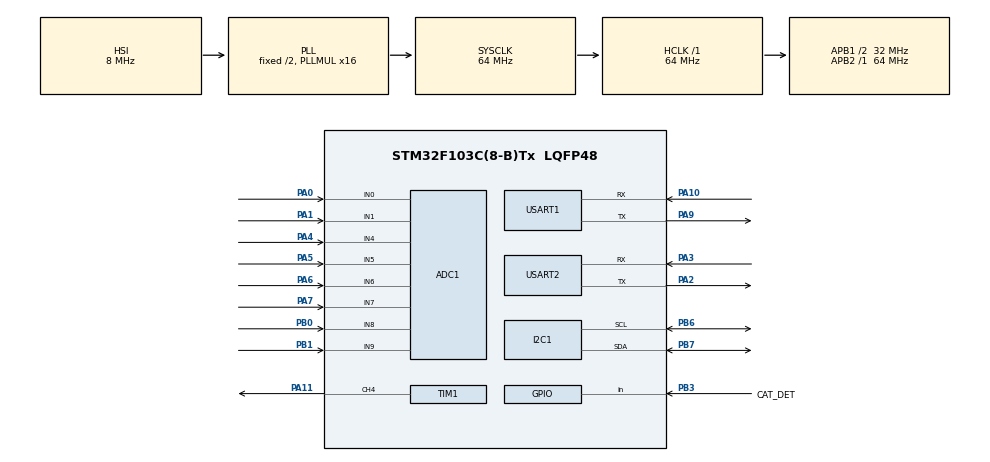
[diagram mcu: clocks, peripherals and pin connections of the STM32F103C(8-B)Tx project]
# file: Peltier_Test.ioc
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ADC1.Channel-0\#ChannelRegularConversion=ADC_CHANNEL_0
ADC1.NbrOfConversionFlag=1
ADC1.Rank-0\#ChannelRegularConversion=1
ADC1.SamplingTime-0\#ChannelRegularConversion=ADC_SAMPLETIME_1CYCLE_5
ADC1.master=1
Mcu.Family=STM32F1
Mcu.Name=STM32F103C(8-B)Tx
Mcu.Package=LQFP48
NVIC.PriorityGroup=NVIC_PRIORITYGROUP_4
NVIC.USART1_IRQn=true\:0\:0\:false\:false\:true\:true\:true\:true
NVIC.USART2_IRQn=true\:0\:0\:false\:false\:true\:true\:true\:true
PA0-WKUP.Signal=ADCx_IN0
PA1.Signal=ADCx_IN1
PA10.Mode=Asynchronous
PA10.Signal=USART1_RX
PA11.Signal=S_TIM1_CH4
PA13.Mode=Serial_Wire
PA13.Signal=SYS_JTMS-SWDIO
PA14.Mode=Serial_Wire
PA14.Signal=SYS_JTCK-SWCLK
PA2.Mode=Asynchronous
PA2.Signal=USART2_TX
PA3.Mode=Asynchronous
PA3.Signal=USART2_RX
PA4.Signal=ADCx_IN4
PA5.Signal=ADCx_IN5
PA6.Signal=ADCx_IN6
PA7.Signal=ADCx_IN7
PA9.Mode=Asynchronous
PA9.Signal=USART1_TX
PB0.Signal=ADCx_IN8
PB1.Signal=ADCx_IN9
PB3.GPIO_Label=CAT_DET
PB3.GPIO_PuPd=GPIO_PULLUP
PB3.Signal=GPIO_Input
PB6.Mode=I2C
PB6.Signal=I2C1_SCL
PB7.Mode=I2C
PB7.Signal=I2C1_SDA
ProjectManager.HeapSize=0x200
ProjectManager.StackSize=0x400
ProjectManager.TargetToolchain=STM32CubeIDE
RCC.ADCPresc=RCC_ADCPCLK2_DIV6
RCC.AHBFreq_Value=64000000
RCC.APB1CLKDivider=RCC_HCLK_DIV2
RCC.APB1Freq_Value=32000000
RCC.APB1TimFreq_Value=64000000
RCC.APB2Freq_Value=64000000
RCC.APB2TimFreq_Value=64000000
RCC.HCLKFreq_Value=64000000
RCC.PLLMUL=RCC_PLL_MUL16
RCC.SYSCLKFreq_VALUE=64000000
RCC.SYSCLKSource=RCC_SYSCLKSOURCE_PLLCLK
RCC.USBFreq_Value=64000000
SH.ADCx_IN0.0=ADC1_IN0,IN0
SH.ADCx_IN1.0=ADC1_IN1,IN1
SH.ADCx_IN4.0=ADC1_IN4,IN4
SH.ADCx_IN5.0=ADC1_IN5,IN5
SH.ADCx_IN6.0=ADC1_IN6,IN6
SH.ADCx_IN7.0=ADC1_IN7,IN7
SH.ADCx_IN8.0=ADC1_IN8,IN8
SH.ADCx_IN9.0=ADC1_IN9,IN9
SH.S_TIM1_CH4.0=TIM1_CH4,PWM Generation4 CH4
TIM1.Channel-PWM\ Generation4\ CH4=TIM_CHANNEL_4
TIM1.Period=9999
TIM1.Prescaler=64-1
TIM1.Pulse-PWM\ Generation4\ CH4=0
USART1.VirtualMode=VM_ASYNC
USART2.VirtualMode=VM_ASYNC
board=custom

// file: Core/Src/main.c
/* USER CODE BEGIN Header */
/**
  ******************************************************************************
  * @file           : main.c
  * @brief          : Main program body
  ******************************************************************************
  * @attention
  *
  * Copyright (c) 2025 STMicroelectronics.
  * All rights reserved.
  *
  * This software is licensed under terms that can be found in the LICENSE file
  * in the root directory of this software component.
  * If no LICENSE file comes with this so7ftware, it is provided AS-IS.
  *
  ******************************************************************************
  */
/* USER CODE END Header */
#include "main.h"
#include "adc.h"
#include "i2c.h"
#include "tim.h"
#include "usart.h"
#include "gpio.h"

void SystemClock_Config(void);

int main(void)
{

  /* MCU Configuration--------------------------------------------------------*/

  /* Reset of all peripherals, Initializes the Flash interface and the Systick. */
  HAL_Init();

  /* Configure the system clock */
  SystemClock_Config();

  /* Initialize all configured peripherals */
  MX_GPIO_Init();
  MX_TIM1_Init();
  MX_USART1_UART_Init();
  MX_ADC1_Init();
  MX_I2C1_Init();
  MX_USART2_UART_Init();
  /* USER CODE BEGIN 2 */
  Test_Init();
  Uart_Init();
  eeprom_test();
#if 1
  Eeprom_All_Read();
#endif

  /* USER CODE END 2 */

  /* Infinite loop */
  while (1)
  {

    /* USER CODE BEGIN 3 */
    Test_While();

  }
  /* USER CODE END 3 */
}

void SystemClock_Config(void)
{
  RCC_OscInitTypeDef RCC_OscInitStruct = {0};
  RCC_ClkInitTypeDef RCC_ClkInitStruct = {0};
  RCC_PeriphCLKInitTypeDef PeriphClkInit = {0};

  /** Initializes the RCC Oscillators according to the specified parameters
  * in the RCC_OscInitTypeDef structure.
  */
  RCC_OscInitStruct.OscillatorType = RCC_OSCILLATORTYPE_HSI;
  RCC_OscInitStruct.HSIState = RCC_HSI_ON;
  RCC_OscInitStruct.HSICalibrationValue = RCC_HSICALIBRATION_DEFAULT;
  RCC_OscInitStruct.PLL.PLLState = RCC_PLL_ON;
  RCC_OscInitStruct.PLL.PLLSource = RCC_PLLSOURCE_HSI_DIV2;
  RCC_OscInitStruct.PLL.PLLMUL = RCC_PLL_MUL16;
  if (HAL_RCC_OscConfig(&RCC_OscInitStruct) != HAL_OK)
  {
    Error_Handler();
  }

  /** Initializes the CPU, AHB and APB buses clocks
  */
  RCC_ClkInitStruct.ClockType = RCC_CLOCKTYPE_HCLK|RCC_CLOCKTYPE_SYSCLK
                              |RCC_CLOCKTYPE_PCLK1|RCC_CLOCKTYPE_PCLK2;
  RCC_ClkInitStruct.SYSCLKSource = RCC_SYSCLKSOURCE_PLLCLK;
  RCC_ClkInitStruct.AHBCLKDivider = RCC_SYSCLK_DIV1;
  RCC_ClkInitStruct.APB1CLKDivider = RCC_HCLK_DIV2;
  RCC_ClkInitStruct.APB2CLKDivider = RCC_HCLK_DIV1;

  if (HAL_RCC_ClockConfig(&RCC_ClkInitStruct, FLASH_LATENCY_2) != HAL_OK)
  {
    Error_Handler();
  }
  PeriphClkInit.PeriphClockSelection = RCC_PERIPHCLK_ADC;
  PeriphClkInit.AdcClockSelection = RCC_ADCPCLK2_DIV6;
  if (HAL_RCCEx_PeriphCLKConfig(&PeriphClkInit) != HAL_OK)
  {
    Error_Handler();
  }
}

void Error_Handler(void)
{
  __disable_irq();
  while (1)
  {
  }
}
